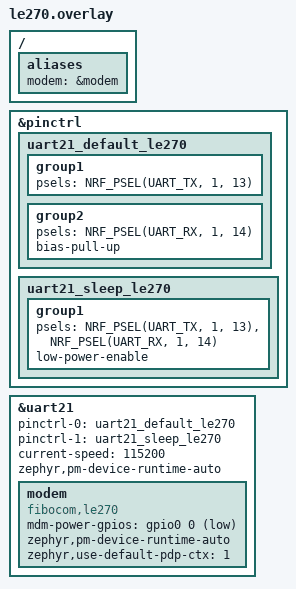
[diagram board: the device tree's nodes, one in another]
/*
 * SPDX-License-Identifier: Apache-2.0
 *
 * Fibocom LE270 modem wired externally to this DK, on uart21 (SoC PERI
 * domain, P1) - the same physical TXD/RXD/PWRKEY pins boards/eg800z.overlay
 * uses, since only one external modem is ever populated on the DK at a
 * time:
 *
 *   TXD     - P1.13 (SoC output -> modem MAIN_RXD)
 *   RXD     - P1.14 (SoC input  <- modem MAIN_TXD)
 *   PWRKEY   - P0.00 (gpio0, active-low)
 *
 * No RTS/CTS: on real hardware (this project's Fibocom LE270 ADP), enabling
 * hw-flow-control here left the async HWFC backend permanently unable to
 * transmit ("Transmit aborted (0 sent)", repeating) - the nRF UARTE with
 * HWFC enabled will not send a byte until it sees its own CTS input
 * asserted, and that never happened, even though the modem's own boot
 * banners (^boot.rom'v, AT command ready, +SIM READY) arrived on RX just
 * fine. Root cause not confirmed (ADP-specific RTS/CTS routing is already
 * atypical here - see the RESET_N/DTR note below), but plain 2-wire
 * TX/RX with no flow control unblocks it: the driver never sends AT+IFC to
 * put the module into hardware-flow-control mode, so its default boot
 * state already expects none.
 *
 * RESET_N and MAIN_DTR are NOT wired here: on the Fibocom LE270 ADP
 * (development board), both are only exposed as onboard physical
 * buttons, not as header pins the DK can drive. Both are optional per
 * zephyr,cellular-modem-device.yaml (only mdm-power-gpios is
 * `required: true`), so this is a supported configuration, not a
 * workaround:
 *  - mdm-reset-gpios only gates zephyr,mdm-reset-behavior's
 *    "toggle_on_recovery" - an automatic RESET_N pulse if the init chat
 *    script ever fails to get responses. Without it, that one
 *    auto-recovery path is unavailable; the ADP's reset button (or a
 *    full power cycle) still works as a manual fallback.
 *  - mdm-dtr-gpios only matters for DTR-gated sleep. The LE270-EU
 *    datasheet lists PSM as unsupported for this variant, so there is no
 *    low-power sleep mode here for DTR to gate in the first place -
 *    leaving it unwired costs nothing for this project's PPP/UDP round
 *    trip.
 *
 * Unlike the EG800Z, this driver does NOT set `autostarts`: the LE270
 * Hardware Guide V2.2 section 4.2 documents a normal PWRKEY power-on pulse
 * (pull low >=650ms, VBAT stable >=30ms first) as the expected method, with
 * no equivalent to the EG800Z's observed "boots on its own, a PWRKEY pulse
 * turns it back off" behavior - unverified on real hardware, but the
 * documented method is the safer default to start from.
 *
 * Polarity for PWRKEY: Hardware Guide V2.2 section 4.2 - active-LOW (pull
 * low to trigger; idle high via the module's own internal pull-up),
 * matching the EG800Z's own PWRKEY convention.
 */
#include <zephyr/dt-bindings/gpio/gpio.h>

&pinctrl {
	uart21_default_le270: uart21_default_le270 {
		group1 {
			psels = <NRF_PSEL(UART_TX, 1, 13)>;
		};

		group2 {
			psels = <NRF_PSEL(UART_RX, 1, 14)>;
			bias-pull-up;
		};
	};

	uart21_sleep_le270: uart21_sleep_le270 {
		group1 {
			psels = <NRF_PSEL(UART_TX, 1, 13)>,
				<NRF_PSEL(UART_RX, 1, 14)>;
			low-power-enable;
		};
	};
};

&uart21 {
	status = "okay";
	pinctrl-0 = <&uart21_default_le270>;
	pinctrl-1 = <&uart21_sleep_le270>;
	pinctrl-names = "default", "sleep";
	current-speed = <115200>;
	zephyr,pm-device-runtime-auto;

	modem: modem {
		compatible = "fibocom,le270";
		mdm-power-gpios = <&gpio0 0 GPIO_ACTIVE_LOW>;
		zephyr,pm-device-runtime-auto;
		/* LE270_driver_optimisation_instructions.md Change 1: real-hardware
		 * diagnostics (AT+CGDCONT?/AT+CGACT?/AT+CGPADDR=1, read both before
		 * and after modem_cellular's generic APN script runs) showed PDP
		 * context 1 already has the gsfleet.cxn APN and a real IP address
		 * from the module's own boot-time attach, completely unchanged by
		 * the framework's AT+CGDCONT=1,"IP","gsfleet.cxn" rewrite (same
		 * value, written every round regardless). A Joulescope current
		 * trace correlated against the log showed that rewrite is what
		 * triggers a ~2s burst of heavy RF re-signaling (RRC reconnect),
		 * coincident with it to within 50ms - almost certainly the real
		 * source of the slow ATD->CONNECT this document flagged. Since the
		 * AT Commands Manual documents AT+CGDCONT's "RequireDataStoreAt
		 * PowerDown: Yes" (confirmed empirically: it's already correct
		 * before this driver ever touches it), there's nothing for the
		 * framework to configure here - setting this skips
		 * MODEM_CELLULAR_STATE_RUN_APN_SCRIPT entirely
		 * (modem_cellular_open_dlci2_event_handler in modem_cellular.c),
		 * so AT+CGDCONT/AT+CGACT are never sent at all and the dial script
		 * goes straight from CMUX/DLCI setup to ATD*99***1# (cid=1 still
		 * explicit there, matching the cid this module's own default
		 * attach already uses - not cid=0 as the binding's generic
		 * description implies, confirmed by the same diagnostics).
		 * Flagged for hardware verification like everything else in this
		 * optimization pass. */
		zephyr,use-default-pdp-ctx = <1>;
	};
};

/ {
	aliases {
		modem = &modem;
	};
};
